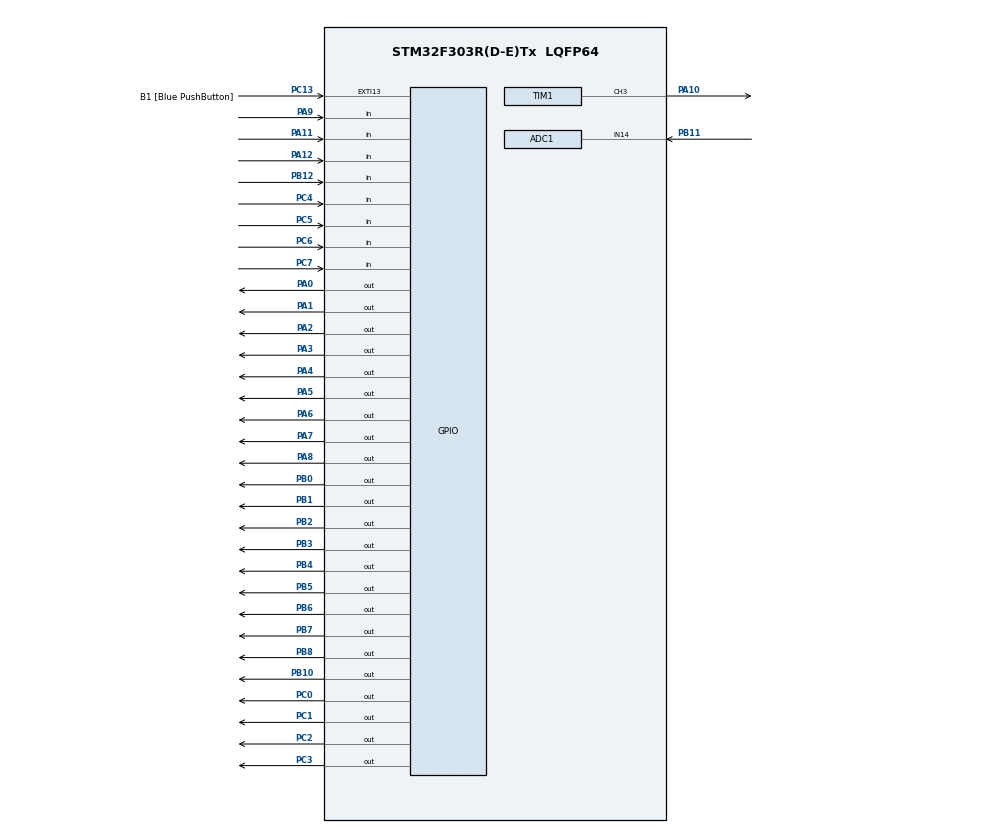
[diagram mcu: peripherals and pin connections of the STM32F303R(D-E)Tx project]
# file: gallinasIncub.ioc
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ADC1.Channel-0\#ChannelRegularConversion=ADC_CHANNEL_14
ADC1.EnableAnalogWatchDog1=true
ADC1.NbrOfConversionFlag=1
ADC1.Offset-0\#ChannelRegularConversion=0
ADC1.OffsetNumber-0\#ChannelRegularConversion=ADC_OFFSET_NONE
ADC1.Rank-0\#ChannelRegularConversion=1
ADC1.SamplingTime-0\#ChannelRegularConversion=ADC_SAMPLETIME_1CYCLE_5
ADC1.SamplingTimeOPAMP-0\#ChannelRegularConversion=ADC_SAMPLETIME_19CYCLES_5
ADC1.WatchdogChannel=ADC_CHANNEL_14
ADC1.master=1
Mcu.Family=STM32F3
Mcu.Name=STM32F303R(D-E)Tx
Mcu.Package=LQFP64
NVIC.ADC1_2_IRQn=true\:0\:0\:false\:false\:true\:true\:true\:true
NVIC.PriorityGroup=NVIC_PRIORITYGROUP_0
NVIC.TIM4_IRQn=true\:0\:0\:false\:false\:true\:true\:true\:true
PA0.Signal=GPIO_Output
PA1.Signal=GPIO_Output
PA10.Signal=S_TIM1_CH3
PA11.GPIO_PuPd=GPIO_PULLUP
PA11.Signal=GPIO_Input
PA12.GPIO_PuPd=GPIO_PULLUP
PA12.Signal=GPIO_Input
PA13.GPIO_Label=TMS
PA13.Signal=SYS_JTMS-SWDIO
PA14.GPIO_Label=TCK
PA14.Signal=SYS_JTCK-SWCLK
PA2.Signal=GPIO_Output
PA3.Signal=GPIO_Output
PA4.Signal=GPIO_Output
PA5.Signal=GPIO_Output
PA6.Signal=GPIO_Output
PA7.Signal=GPIO_Output
PA8.Signal=GPIO_Output
PA9.Signal=GPIO_Input
PB0.Signal=GPIO_Output
PB1.Signal=GPIO_Output
PB10.Signal=GPIO_Output
PB11.Mode=IN14-Single-Ended
PB11.Signal=ADC1_IN14
PB12.Signal=GPIO_Input
PB2.Signal=GPIO_Output
PB3.Signal=GPIO_Output
PB4.Signal=GPIO_Output
PB5.Signal=GPIO_Output
PB6.Signal=GPIO_Output
PB7.Signal=GPIO_Output
PB8.Signal=GPIO_Output
PC0.Signal=GPIO_Output
PC1.Signal=GPIO_Output
PC13.GPIO_Label=B1 [Blue PushButton]
PC13.GPIO_ModeDefaultEXTI=GPIO_MODE_IT_FALLING
PC13.Signal=GPXTI13
PC14-OSC32_IN.Signal=RCC_OSC32_IN
PC15-OSC32_OUT.Signal=RCC_OSC32_OUT
PC2.Signal=GPIO_Output
PC3.Signal=GPIO_Output
PC4.GPIO_PuPd=GPIO_PULLUP
PC4.Signal=GPIO_Input
PC5.GPIO_PuPd=GPIO_PULLUP
PC5.Signal=GPIO_Input
PC6.Signal=GPIO_Input
PC7.Signal=GPIO_Input
PF0-OSC_IN.Signal=RCC_OSC_IN
PF1-OSC_OUT.Signal=RCC_OSC_OUT
ProjectManager.HeapSize=0x200
ProjectManager.StackSize=0x400
ProjectManager.TargetToolchain=STM32CubeIDE
RCC.AHBFreq_Value=36000000
RCC.APB1CLKDivider=RCC_HCLK_DIV2
RCC.APB1Freq_Value=18000000
RCC.APB1TimFreq_Value=36000000
RCC.APB2Freq_Value=36000000
RCC.APB2TimFreq_Value=36000000
RCC.CortexFreq_Value=36000000
RCC.HCLKFreq_Value=36000000
RCC.HSE_VALUE=8000000
RCC.HSI_VALUE=8000000
RCC.LSE_VALUE=32768
RCC.PLLM=8
RCC.PLLMUL=RCC_PLL_MUL9
RCC.PLLN=336
RCC.PLLP=RCC_PLLP_DIV4
RCC.PLLQ=7
RCC.RCC_PLLsource_Clock_Source_FROM_HSE=RCC_HSE_PREDIV_DIV2
RCC.SYSCLKFreq_VALUE=36000000
RCC.SYSCLKSourceVirtual=RCC_SYSCLKSOURCE_PLLCLK
RCC.USBFreq_Value=36000000
SH.S_TIM1_CH3.0=TIM1_CH3,PWM Generation3 CH3
TIM1.Channel-PWM\ Generation3\ CH3=TIM_CHANNEL_3
VP_TIM1_VS_ClockSourceINT.Mode=Internal
VP_TIM4_VS_ClockSourceINT.Mode=Internal
board=NUCLEO-F303RE

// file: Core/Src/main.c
#include "main.h"
#include "adc.h"
#include "tim.h"
#include "gpio.h"

/* USER CODE BEGIN Includes */
#include "lcd.h"
#include "keypad_logic.h"
#include "buzzer.h"
#include "servo.h"
/* USER CODE END Includes */

void SystemClock_Config(void)
{
  // configuración del reloj (CubeMX la genera)
}

int main(void)
{
  HAL_Init();
  SystemClock_Config();

  MX_GPIO_Init();
  MX_TIM4_Init();
  MX_ADC1_Init();
  MX_TIM1_Init();

  lcd_init();
  buzzer_init();
  servo_init();
  keypad_logic_init();

  HAL_TIM_PWM_Start(&htim1_sm, TIM_CHANNEL_3); // PWM para servo

  lcd_clear();
  lcd_print_line(0, "Tiempo:");
  lcd_print_line(1, "Ingrese segs");

  while (1)
  {
    KeypadEvent evento = keypad_logic_update();

    if (evento == KEYPAD_EVENT_CONFIRMADO)
    {
      uint16_t tiempo = get_tiempo_confirmado();

      lcd_clear();
      lcd_print_line(0, "CONFIRMADO");
      lcd_print_number(1, tiempo);
      HAL_Delay(1500);

      for (uint16_t i = tiempo; i > 0; i--)
      {
        lcd_clear();
        lcd_print_line(0, "Contando...");
        lcd_print_number(1, i);
        HAL_Delay(1000);

        if (i % 5 == 0)
        {
          lcd_clear();
          lcd_print_line(0, "Midiendo temp...");
          HAL_Delay(1500);

          uint16_t temp_adc = read_temperature();
          lcd_clear();
          lcd_print_line(0, "Temp ADC:");
          lcd_print_number(1, temp_adc);
          HAL_Delay(1000);

          if (temp_adc < 471) // ≈38°C
          {
            lcd_clear();
            lcd_print_line(0, "ALERTA");
           // buzzer_beep(2);
            HAL_Delay(1500);
          }
        }
      }

      lcd_clear();
      lcd_print_line(0, "Ciclo finalizado");
      HAL_Delay(1500);

      lcd_clear();
      lcd_print_line(0, "Girando servo...");
      servo_set_speed(100);
      HAL_Delay(1000);
      servo_set_speed(-100);
      HAL_Delay(1000);
      servo_set_speed(0);

      reset_entrada();
      lcd_clear();
      lcd_print_line(0, "Tiempo:");
      lcd_print_line(1, "Ingrese segs");
    }

    if (evento == KEYPAD_EVENT_CANCELADO)
    {
      lcd_clear();
      lcd_print_line(0, "Cancelado");
      HAL_Delay(1000);
      lcd_print_line(0, "Tiempo:");
      lcd_print_line(1, "Ingrese segs");
    }
  }
}

void Error_Handler(void)
{
  __disable_irq();
  while (1) {}
}
